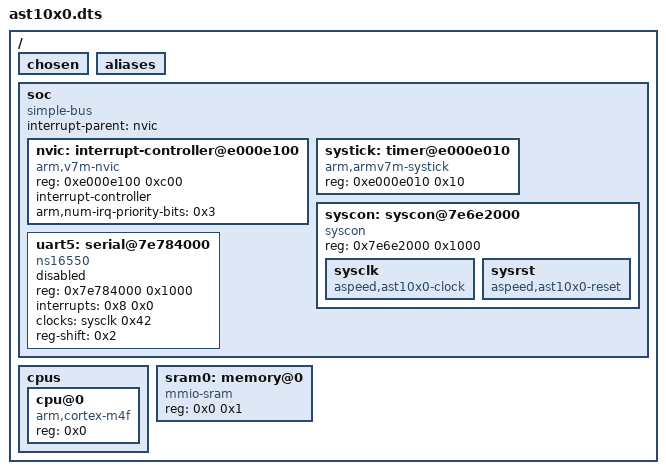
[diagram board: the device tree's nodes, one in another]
/dts-v1/;

/ {
	#address-cells = < 0x1 >;
	#size-cells = < 0x1 >;
	chosen {
	};
	aliases {
	};
	soc {
		#address-cells = < 0x1 >;
		#size-cells = < 0x1 >;
		compatible = "simple-bus";
		interrupt-parent = < &nvic >;
		ranges;
		nvic: interrupt-controller@e000e100 {
			#address-cells = < 0x1 >;
			compatible = "arm,v7m-nvic";
			reg = < 0xe000e100 0xc00 >;
			interrupt-controller;
			#interrupt-cells = < 0x2 >;
			arm,num-irq-priority-bits = < 0x3 >;
			phandle = < 0x1 >;
		};
		systick: timer@e000e010 {
			compatible = "arm,armv7m-systick";
			reg = < 0xe000e010 0x10 >;
		};
		syscon: syscon@7e6e2000 {
			compatible = "syscon";
			reg = < 0x7e6e2000 0x1000 >;
			sysclk: sysclk {
				compatible = "aspeed,ast10x0-clock";
				#clock-cells = < 0x1 >;
				phandle = < 0x2 >;
			};
			sysrst: sysrst {
				compatible = "aspeed,ast10x0-reset";
				#reset-cells = < 0x1 >;
			};
		};
		uart5: serial@7e784000 {
			compatible = "ns16550";
			reg = < 0x7e784000 0x1000 >;
			interrupts = < 0x8 0x0 >;
			clocks = < &sysclk 0x42 >;
			status = "disabled";
			reg-shift = < 0x2 >;
		};
	};
	cpus {
		#address-cells = < 0x1 >;
		#size-cells = < 0x0 >;
		cpu@0 {
			device_type = "cpu";
			compatible = "arm,cortex-m4f";
			reg = < 0x0 >;
		};
	};
	sram0: memory@0 {
		compatible = "mmio-sram";
		reg = < 0x0 0x1 >;
	};
};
